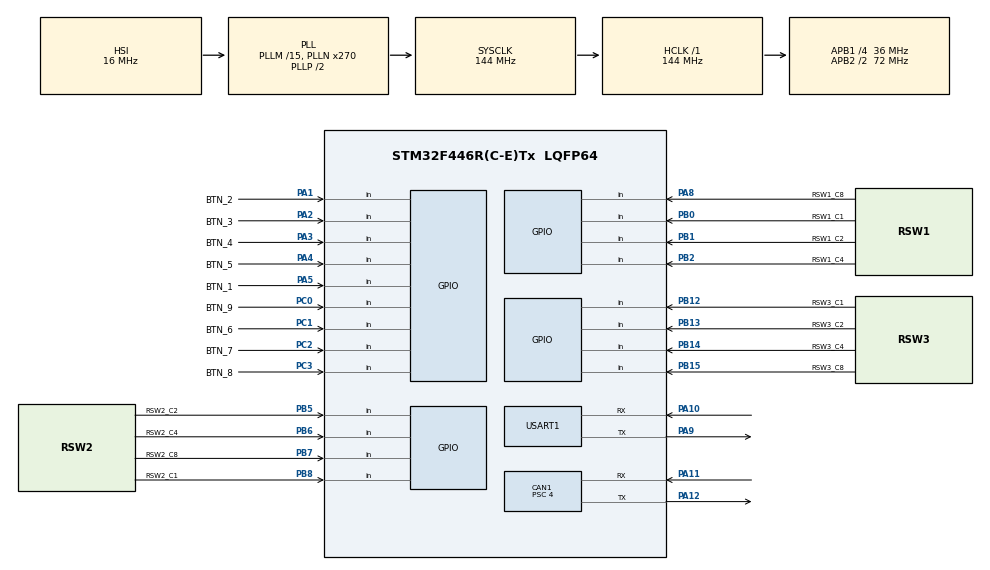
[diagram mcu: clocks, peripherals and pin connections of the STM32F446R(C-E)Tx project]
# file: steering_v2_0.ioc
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CAN1.ABOM=ENABLE
CAN1.BS1=CAN_BS1_15TQ
CAN1.BS2=CAN_BS2_2TQ
CAN1.CalculateBaudRate=500000
CAN1.CalculateTimeBit=2000
CAN1.CalculateTimeQuantum=111.11111111111111
CAN1.Mode=CAN_MODE_NORMAL
CAN1.Prescaler=4
Mcu.Family=STM32F4
Mcu.Name=STM32F446R(C-E)Tx
Mcu.Package=LQFP64
NVIC.PriorityGroup=NVIC_PRIORITYGROUP_4
PA1.GPIO_Label=BTN_2
PA1.GPIO_PuPd=GPIO_PULLUP
PA1.Signal=GPIO_Input
PA10.Mode=Asynchronous
PA10.Signal=USART1_RX
PA11.Mode=CAN_Activate
PA11.Signal=CAN1_RX
PA12.Mode=CAN_Activate
PA12.Signal=CAN1_TX
PA13.Mode=Serial_Wire
PA13.Signal=SYS_JTMS-SWDIO
PA14.Mode=Serial_Wire
PA14.Signal=SYS_JTCK-SWCLK
PA2.GPIO_Label=BTN_3
PA2.GPIO_PuPd=GPIO_PULLUP
PA2.Signal=GPIO_Input
PA3.GPIO_Label=BTN_4
PA3.GPIO_PuPd=GPIO_PULLUP
PA3.Signal=GPIO_Input
PA4.GPIO_Label=BTN_5
PA4.GPIO_PuPd=GPIO_PULLUP
PA4.Signal=GPIO_Input
PA5.GPIO_Label=BTN_1
PA5.GPIO_Mode=GPIO_MODE_INPUT
PA5.GPIO_PuPd=GPIO_PULLUP
PA5.Signal=GPIO_Input
PA8.GPIO_Label=RSW1_C8
PA8.GPIO_PuPd=GPIO_PULLDOWN
PA8.Signal=GPIO_Input
PA9.Mode=Asynchronous
PA9.Signal=USART1_TX
PB0.GPIO_Label=RSW1_C1
PB0.GPIO_PuPd=GPIO_PULLDOWN
PB0.Signal=GPIO_Input
PB1.GPIO_Label=RSW1_C2
PB1.GPIO_PuPd=GPIO_PULLDOWN
PB1.Signal=GPIO_Input
PB12.GPIO_Label=RSW3_C1
PB12.GPIO_PuPd=GPIO_PULLDOWN
PB12.Signal=GPIO_Input
PB13.GPIO_Label=RSW3_C2
PB13.GPIO_PuPd=GPIO_PULLDOWN
PB13.Signal=GPIO_Input
PB14.GPIO_Label=RSW3_C4
PB14.GPIO_PuPd=GPIO_PULLDOWN
PB14.Signal=GPIO_Input
PB15.GPIO_Label=RSW3_C8
PB15.GPIO_PuPd=GPIO_PULLDOWN
PB15.Signal=GPIO_Input
PB2.GPIO_Label=RSW1_C4
PB2.GPIO_PuPd=GPIO_PULLDOWN
PB2.Signal=GPIO_Input
PB5.GPIO_Label=RSW2_C2
PB5.GPIO_PuPd=GPIO_PULLDOWN
PB5.Signal=GPIO_Input
PB6.GPIO_Label=RSW2_C4
PB6.GPIO_PuPd=GPIO_PULLDOWN
PB6.Signal=GPIO_Input
PB7.GPIO_Label=RSW2_C8
PB7.GPIO_PuPd=GPIO_PULLDOWN
PB7.Signal=GPIO_Input
PB8.GPIO_Label=RSW2_C1
PB8.GPIO_PuPd=GPIO_PULLDOWN
PB8.Signal=GPIO_Input
PC0.GPIO_Label=BTN_9
PC0.GPIO_PuPd=GPIO_PULLUP
PC0.Signal=GPIO_Input
PC1.GPIO_Label=BTN_6
PC1.GPIO_PuPd=GPIO_PULLUP
PC1.Signal=GPIO_Input
PC2.GPIO_Label=BTN_7
PC2.GPIO_PuPd=GPIO_PULLUP
PC2.Signal=GPIO_Input
PC3.GPIO_Label=BTN_8
PC3.GPIO_PuPd=GPIO_PULLUP
PC3.Signal=GPIO_Input
PH0-OSC_IN.Mode=HSE-External-Oscillator
PH0-OSC_IN.Signal=RCC_OSC_IN
PH1-OSC_OUT.Mode=HSE-External-Oscillator
PH1-OSC_OUT.Signal=RCC_OSC_OUT
ProjectManager.HeapSize=0x200
ProjectManager.StackSize=0x400
ProjectManager.TargetToolchain=Makefile
RCC.AHBFreq_Value=144000000
RCC.APB1CLKDivider=RCC_HCLK_DIV4
RCC.APB1Freq_Value=36000000
RCC.APB1TimFreq_Value=72000000
RCC.APB2CLKDivider=RCC_HCLK_DIV2
RCC.APB2Freq_Value=72000000
RCC.APB2TimFreq_Value=144000000
RCC.CortexFreq_Value=144000000
RCC.HCLKFreq_Value=144000000
RCC.PLLM=15
RCC.PLLN=270
RCC.SYSCLKFreq_VALUE=144000000
RCC.SYSCLKSource=RCC_SYSCLKSOURCE_PLLCLK
RCC.USBFreq_Value=144000000
RCC.VCOOutputFreq_Value=288000000
USART1.VirtualMode=VM_ASYNC
board=custom

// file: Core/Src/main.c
/* USER CODE BEGIN Header */
/**
  ******************************************************************************
  * @file           : main.c
  * @brief          : Main program body
  ******************************************************************************
  * @attention
  *
  * Copyright (c) 2025 STMicroelectronics.
  * All rights reserved.
  *
  * This software is licensed under terms that can be found in the LICENSE file
  * in the root directory of this software component.
  * If no LICENSE file comes with this software, it is provided AS-IS.
  *
  ******************************************************************************
  */
/* USER CODE END Header */
#include "main.h"
#include "can.h"
#include "usart.h"
#include "gpio.h"

/* USER CODE BEGIN Includes */
#include "steering.h"

/* USER CODE END Includes */

void SystemClock_Config(void);

int main(void)
{

  /* MCU Configuration--------------------------------------------------------*/

  /* Reset of all peripherals, Initializes the Flash interface and the Systick. */
  HAL_Init();

  /* Configure the system clock */
  SystemClock_Config();

  /* Initialize all configured peripherals */
  MX_GPIO_Init();
  MX_CAN1_Init();
  MX_USART1_UART_Init();
  /* USER CODE BEGIN 2 */
  Steering_Init();
  /* USER CODE END 2 */

  /* Infinite loop */
  /* USER CODE BEGIN WHILE */
  while (1) {
    Steering_Run();
    /* USER CODE END WHILE */

  }
}

void SystemClock_Config(void)
{
  RCC_OscInitTypeDef RCC_OscInitStruct = {0};
  RCC_ClkInitTypeDef RCC_ClkInitStruct = {0};

  /** Configure the main internal regulator output voltage
  */
  __HAL_RCC_PWR_CLK_ENABLE();
  __HAL_PWR_VOLTAGESCALING_CONFIG(PWR_REGULATOR_VOLTAGE_SCALE1);

  /** Initializes the RCC Oscillators according to the specified parameters
  * in the RCC_OscInitTypeDef structure.
  */
  RCC_OscInitStruct.OscillatorType = RCC_OSCILLATORTYPE_HSI;
  RCC_OscInitStruct.HSIState = RCC_HSI_ON;
  RCC_OscInitStruct.HSICalibrationValue = RCC_HSICALIBRATION_DEFAULT;
  RCC_OscInitStruct.PLL.PLLState = RCC_PLL_ON;
  RCC_OscInitStruct.PLL.PLLSource = RCC_PLLSOURCE_HSI;
  RCC_OscInitStruct.PLL.PLLM = 15;
  RCC_OscInitStruct.PLL.PLLN = 270;
  RCC_OscInitStruct.PLL.PLLP = RCC_PLLP_DIV2;
  RCC_OscInitStruct.PLL.PLLQ = 2;
  RCC_OscInitStruct.PLL.PLLR = 2;
  if (HAL_RCC_OscConfig(&RCC_OscInitStruct) != HAL_OK)
  {
    Error_Handler();
  }

  /** Initializes the CPU, AHB and APB buses clocks
  */
  RCC_ClkInitStruct.ClockType = RCC_CLOCKTYPE_HCLK|RCC_CLOCKTYPE_SYSCLK
                              |RCC_CLOCKTYPE_PCLK1|RCC_CLOCKTYPE_PCLK2;
  RCC_ClkInitStruct.SYSCLKSource = RCC_SYSCLKSOURCE_PLLCLK;
  RCC_ClkInitStruct.AHBCLKDivider = RCC_SYSCLK_DIV1;
  RCC_ClkInitStruct.APB1CLKDivider = RCC_HCLK_DIV4;
  RCC_ClkInitStruct.APB2CLKDivider = RCC_HCLK_DIV2;

  if (HAL_RCC_ClockConfig(&RCC_ClkInitStruct, FLASH_LATENCY_4) != HAL_OK)
  {
    Error_Handler();
  }
}

void Error_Handler(void)
{
  __disable_irq();
  while (1)
  {
  }
}
